# STM32F0x8 register map
File version: 1.3
CPU: CM0 r0p0, little endian, no MPU, no FPU, 3 interrupt priority bits
Registers are 32-bit, read-write, reset 0x0 unless marked. A register's access mark holds for its fields unless they carry their own. Offsets are from the block's base; [hi:lo] are bit positions; {n}, {i} and the like mark numbered series.

## SYSCFG_COMP — System configuration controller
Base 0x40010000
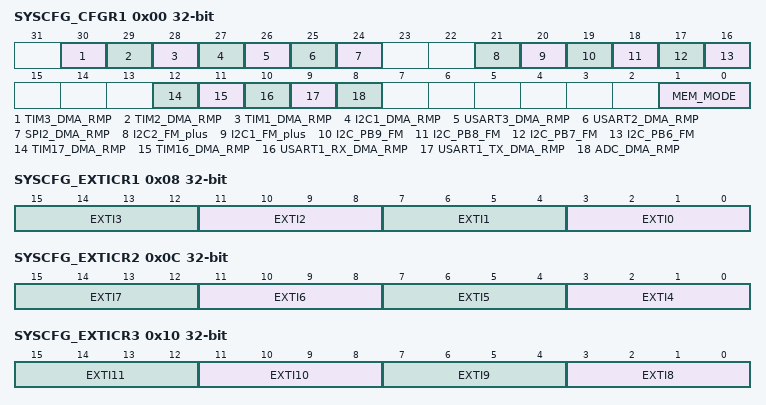
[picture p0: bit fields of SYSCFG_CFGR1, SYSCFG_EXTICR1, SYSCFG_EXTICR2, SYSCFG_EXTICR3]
0x00 SYSCFG_CFGR1 — configuration register 1
  [30] TIM3_DMA_RMP — TIM3 DMA request remapping bit
  [29] TIM2_DMA_RMP — TIM2 DMA request remapping bit
  [28] TIM1_DMA_RMP — TIM1 DMA request remapping bit
  [27] I2C1_DMA_RMP — I2C1 DMA request remapping bit
  [26] USART3_DMA_RMP — USART3 DMA request remapping bit
  [25] USART2_DMA_RMP — USART2 DMA request remapping bit
  [24] SPI2_DMA_RMP — SPI2 DMA request remapping bit
  [21] I2C2_FM_plus — FM+ driving capability activation for I2C2
  [20] I2C1_FM_plus — FM+ driving capability activation for I2C1
  [19] I2C_PB9_FM — Fast Mode Plus (FM+) driving capability activation bits.
  [18] I2C_PB8_FM — Fast Mode Plus (FM+) driving capability activation bits.
  [17] I2C_PB7_FM — Fast Mode Plus (FM+) driving capability activation bits.
  [16] I2C_PB6_FM — Fast Mode Plus (FM plus) driving capability activation bits.
  [12] TIM17_DMA_RMP — TIM17 DMA request remapping bit
  [11] TIM16_DMA_RMP — TIM16 DMA request remapping bit
  [10] USART1_RX_DMA_RMP — USART1_RX DMA request remapping bit
  [9] USART1_TX_DMA_RMP — USART1_TX DMA remapping bit
  [8] ADC_DMA_RMP — ADC DMA remapping bit
  [1:0] MEM_MODE — Memory mapping selection bits
0x08 SYSCFG_EXTICR1 — external interrupt configuration register 1
  [4n+3:4n] EXTI{n} (n=0..3) — EXTI {n} configuration bits
0x0C SYSCFG_EXTICR2 — external interrupt configuration register 2
  [4n-13:4n-16] EXTI{n} (n=4..7) — EXTI {n} configuration bits
0x10 SYSCFG_EXTICR3 — external interrupt configuration register 3
  [4n-29:4n-32] EXTI{n} (n=8..11) — EXTI {n} configuration bits
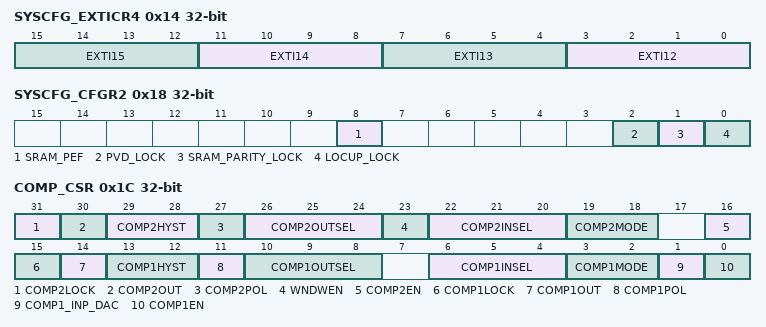
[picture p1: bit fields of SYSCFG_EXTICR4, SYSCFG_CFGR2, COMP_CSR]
0x14 SYSCFG_EXTICR4 — external interrupt configuration register 4
  [4n-45:4n-48] EXTI{n} (n=12..15) — EXTI {n} configuration bits
0x18 SYSCFG_CFGR2 — configuration register 2
  [8] SRAM_PEF — SRAM parity flag
  [2] PVD_LOCK — PVD lock enable bit
  [1] SRAM_PARITY_LOCK — SRAM parity lock bit
  [0] LOCUP_LOCK — Cortex-M0 LOCKUP bit enable bit
0x1C COMP_CSR access per field — control and status register
  [31] COMP2LOCK rw — Comparator 2 lock
  [30] COMP2OUT ro — Comparator 2 output
  [29:28] COMP2HYST rw — Comparator 2 hysteresis
  [27] COMP2POL rw — Comparator 2 output polarity
  [26:24] COMP2OUTSEL rw — Comparator 2 output selection
  [23] WNDWEN rw — Window mode enable
  [22:20] COMP2INSEL rw — Comparator 2 inverting input selection
  [19:18] COMP2MODE rw — Comparator 2 mode
  [16] COMP2EN rw — Comparator 2 enable
  [15] COMP1LOCK rw — Comparator 1 lock
  [14] COMP1OUT ro — Comparator 1 output
  [13:12] COMP1HYST rw — Comparator 1 hysteresis
  [11] COMP1POL rw — Comparator 1 output polarity
  [10:8] COMP1OUTSEL rw — Comparator 1 output selection
  [6:4] COMP1INSEL rw — Comparator 1 inverting input selection
  [3:2] COMP1MODE rw — Comparator 1 mode
  [1] COMP1_INP_DAC rw
  [0] COMP1EN rw — Comparator 1 enable

## ADC — Analog-to-digital converter
Base 0x40012400
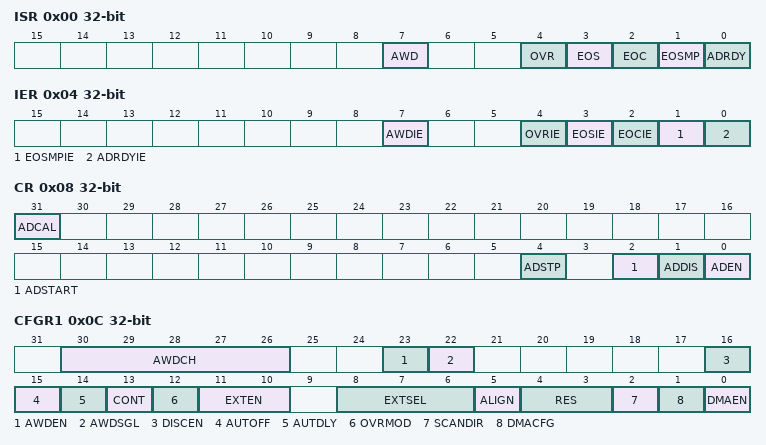
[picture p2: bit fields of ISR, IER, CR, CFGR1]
0x00 ISR — interrupt and status register
  [7] AWD — Analog watchdog flag
  [4] OVR — ADC overrun
  [3] EOS — End of sequence flag
  [2] EOC — End of conversion flag
  [1] EOSMP — End of sampling flag
  [0] ADRDY — ADC ready
0x04 IER — interrupt enable register
  [7] AWDIE — Analog watchdog interrupt enable
  [4] OVRIE — Overrun interrupt enable
  [3] EOSIE — End of conversion sequence interrupt enable
  [2] EOCIE — End of conversion interrupt enable
  [1] EOSMPIE — End of sampling flag interrupt enable
  [0] ADRDYIE — ADC ready interrupt enable
0x08 CR — control register
  [31] ADCAL — ADC calibration
  [4] ADSTP — ADC stop conversion command
  [2] ADSTART — ADC start conversion command
  [1] ADDIS — ADC disable command
  [0] ADEN — ADC enable command
0x0C CFGR1 — configuration register 1
  [30:26] AWDCH — Analog watchdog channel selection
  [23] AWDEN — Analog watchdog enable
  [22] AWDSGL — Enable the watchdog on a single channel or on all channels
  [16] DISCEN — Discontinuous mode
  [15] AUTOFF — Auto-off mode
  [14] AUTDLY — Auto-delayed conversion mode
  [13] CONT — Single / continuous conversion mode
  [12] OVRMOD — Overrun management mode
  [11:10] EXTEN — External trigger enable and polarity selection
  [8:6] EXTSEL — External trigger selection
  [5] ALIGN — Data alignment
  [4:3] RES — Data resolution
  [2] SCANDIR — Scan sequence direction
  [1] DMACFG — Direct memery access configuration
  [0] DMAEN — Direct memory access enable
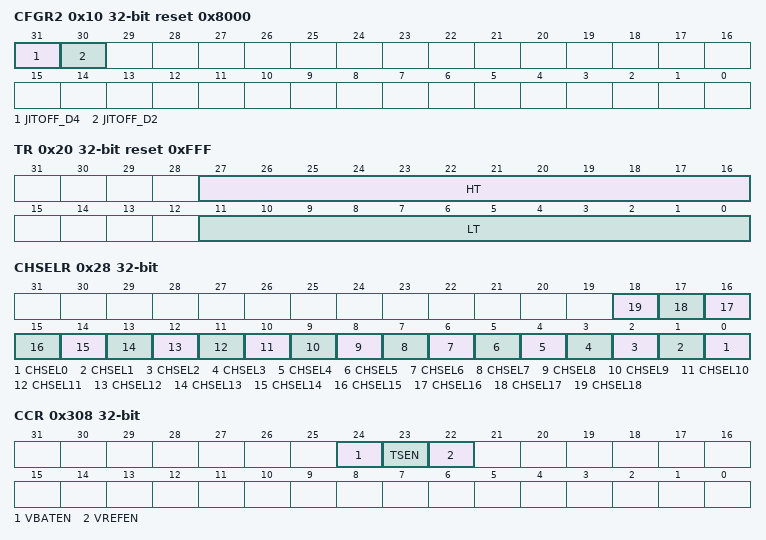
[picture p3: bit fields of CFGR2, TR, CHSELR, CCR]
0x10 CFGR2 reset 0x8000 — configuration register 2
  [31] JITOFF_D4, [30] JITOFF_D2
0x14 SMPR — sampling time register
  [2:0] SMPR — Sampling time selection
0x20 TR reset 0xFFF — watchdog threshold register
  [27:16] HT — Analog watchdog higher threshold
  [11:0] LT — Analog watchdog lower threshold
0x28 CHSELR — channel selection register
  [n] CHSEL{n} (n=0..18) — Channel-x selection
0x40 DR ro — data register
  [15:0] DATA — Converted data
0x308 CCR — common configuration register
  [24] VBATEN — VBAT enable
  [23] TSEN — Temperature sensor enable
  [22] VREFEN — Temperature sensor and VREFINT enable
